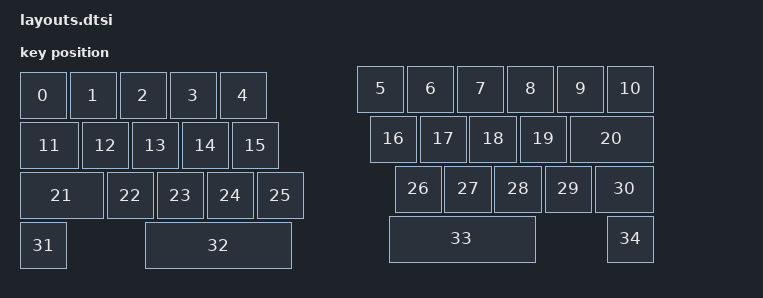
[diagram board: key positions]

#include <physical_layouts.dtsi>
/ {
    physical_layout0: physical_layout0 {
        compatible = "zmk,physical-layout";
        display-name = "Layout";
        keys
            = <&key_physical_attrs 100 100 (-50) 13 0 0 0>
			,<&key_physical_attrs 100 100 50 13 0 0 0>
			,<&key_physical_attrs 100 100 150 13 0 0 0>
			,<&key_physical_attrs 100 100 250 13 0 0 0>
			,<&key_physical_attrs 100 100 350 13 0 0 0>
			,<&key_physical_attrs 100 100 625 0 0 0 0>
			,<&key_physical_attrs 100 100 725 0 0 0 0>
			,<&key_physical_attrs 100 100 825 0 0 0 0>
			,<&key_physical_attrs 100 100 925 0 0 0 0>
			,<&key_physical_attrs 100 100 1025 0 0 0 0>
			,<&key_physical_attrs 100 100 1125 0 0 0 0>
			,<&key_physical_attrs 125 100 (-50) 113 0 0 0>
			,<&key_physical_attrs 100 100 75 113 0 0 0>
			,<&key_physical_attrs 100 100 175 113 0 0 0>
			,<&key_physical_attrs 100 100 275 113 0 0 0>
			,<&key_physical_attrs 100 100 375 113 0 0 0>
			,<&key_physical_attrs 100 100 650 100 0 0 0>
			,<&key_physical_attrs 100 100 750 100 0 0 0>
			,<&key_physical_attrs 100 100 850 100 0 0 0>
			,<&key_physical_attrs 100 100 950 100 0 0 0>
			,<&key_physical_attrs 175 100 1050 100 0 0 0>
			,<&key_physical_attrs 175 100 (-50) 213 0 0 0>
			,<&key_physical_attrs 100 100 125 213 0 0 0>
			,<&key_physical_attrs 100 100 225 213 0 0 0>
			,<&key_physical_attrs 100 100 325 213 0 0 0>
			,<&key_physical_attrs 100 100 425 213 0 0 0>
			,<&key_physical_attrs 100 100 700 200 0 0 0>
			,<&key_physical_attrs 100 100 800 200 0 0 0>
			,<&key_physical_attrs 100 100 900 200 0 0 0>
			,<&key_physical_attrs 100 100 1000 200 0 0 0>
			,<&key_physical_attrs 125 100 1100 200 0 0 0>
			,<&key_physical_attrs 100 100 (-50) 313 0 0 0>
			,<&key_physical_attrs 300 100 200 313 0 0 0>
			,<&key_physical_attrs 300 100 688 300 0 0 0>
			,<&key_physical_attrs 100 100 1125 300 0 0 0>
            ;
    };
};
    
